# PIC32CZ8110CA80176 register map
Vendor: Microchip Technology; Series: PIC32CZCA80; File version: 0
CPU: CM7 r1p1, selectable endian, MPU, FPU, 3 interrupt priority bits
Registers are 32-bit, read-write, reset 0x0 unless marked. A register's access mark holds for its fields unless they carry their own. Offsets are from the block's base; [hi:lo] are bit positions; {n}, {i} and the like mark numbered series; <NAME> marks a mode.

## FPU — Floating Point Unit
Base 0xE000EF30; register names take the prefix FPU_
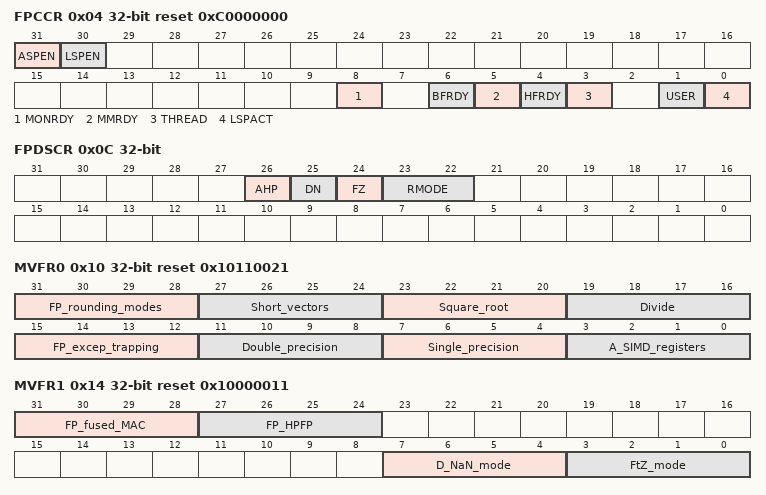
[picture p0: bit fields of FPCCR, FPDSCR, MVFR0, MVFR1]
0x04 FPCCR reset 0xC0000000 — Floating-Point Context Control Register
  [31] ASPEN, [30] LSPEN, [8] MONRDY, [6] BFRDY, [5] MMRDY, [4] HFRDY, [3] THREAD, [1] USER, [0] LSPACT
0x08 FPCAR — Floating-Point Context Address Register
  [31:3] ADDRESS — Address for FP registers in exception stack frame
0x0C FPDSCR — Floating-Point Default Status Control Register
  [26] AHP — Default value for FPSCR.AHP
  [25] DN — Default value for FPSCR.DN
  [24] FZ — Default value for FPSCR.FZ
  [23:22] RMODE — Default value for FPSCR.RMODE
    0=RN (Round to Nearest); 1=RP (Round towards Positive Infinity); 2=RM (Round towards Negative Infinity); 3=RZ (Round towards Zero)
0x10 MVFR0 ro reset 0x10110021 — Media and FP Feature Register 0
  [31:28] FP_rounding_modes, [27:24] Short_vectors, [23:20] Square_root, [19:16] Divide, [15:12] FP_excep_trapping, [11:8] Double_precision, [7:4] Single_precision, [3:0] A_SIMD_registers
0x14 MVFR1 ro reset 0x10000011 — Media and FP Feature Register 1
  [31:28] FP_fused_MAC, [27:24] FP_HPFP, [7:4] D_NaN_mode, [3:0] FtZ_mode
0x18 MVFR2 ro reset 0x40 — Media and FP Feature Register 2

## FREQM — Frequency Meter
Base 0x44060000; register names take the prefix FREQM_
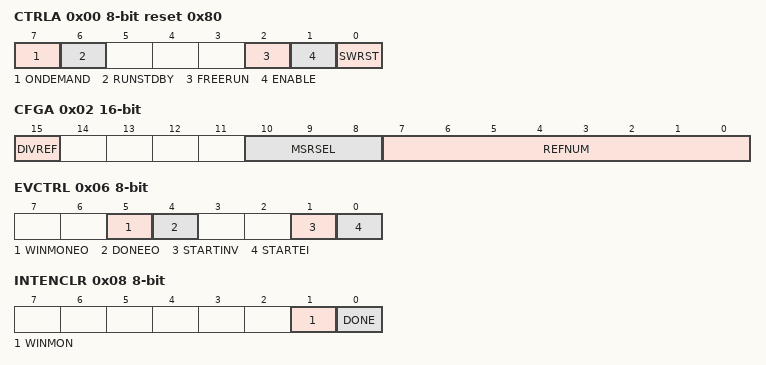
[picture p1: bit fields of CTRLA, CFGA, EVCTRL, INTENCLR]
0x00 CTRLA 8-bit reset 0x80 — Control A Register
  [7] ONDEMAND — On Demand Control
  [6] RUNSTDBY — Run In Standby
  [2] FREERUN — Free Running Mode
  [1] ENABLE
  [0] SWRST — Software Reset
0x01 CTRLB 8-bit wo — Control B Register
  [0] START — Start Measurement
0x02 CFGA 16-bit — Config A Register
  [15] DIVREF — Divide Reference Clock
    0=DIV1 (The reference clock is divided by 1); 1=DIV8 (The reference clock is divided by 8)
  [10:8] MSRSEL — Measurement Clock Selection
    0=GCLK (GCLK Input Clock); 1=CPU (CPU Input Clock)
  [7:0] REFNUM — Number of Reference Clock Cycles
0x04 CTRLC 8-bit — Control C Register
  [2:0] WINMODE — Window Monitor Mode
    0=DISABLE (No window mode (default)); 1=MODE1 (VALUE > WINLT); 2=MODE2 (VALUE < WINUT); 3=MODE3 (WINLT < VALUE < WINUT); 4=MODE4 (!(WINLT < VALUE < WINUT))
0x06 EVCTRL 8-bit — Event Control Register
  [5] WINMONEO — Window Monitor Event Out
  [4] DONEEO — Measurement Done Event Out
  [1] STARTINV — Start Measurement Event Invert Enable
  [0] STARTEI — Start Measurement Event Input Enable
0x08 INTENCLR 8-bit — Interrupt Enable Clear Register
  [1] WINMON — Window Monitor Interrupt Disable
  [0] DONE — Measurement Done Interrupt Disable
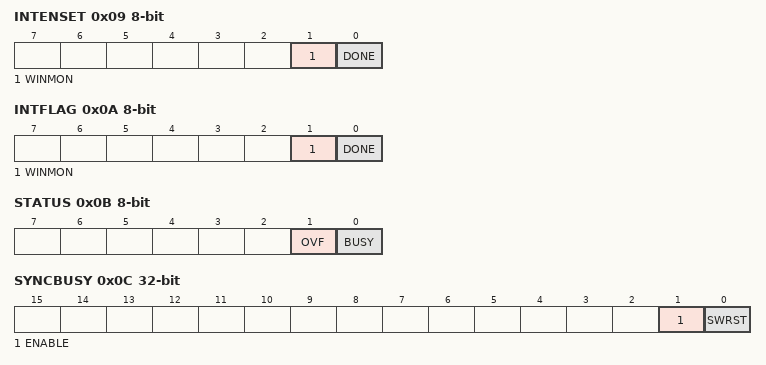
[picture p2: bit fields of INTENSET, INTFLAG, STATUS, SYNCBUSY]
0x09 INTENSET 8-bit — Interrupt Enable Set Register
  [1] WINMON — Window Monitor Interrupt Enable
  [0] DONE — Measurement Done Interrupt Enable
0x0A INTFLAG 8-bit — Interrupt Flag Register
  [1] WINMON — Window Monitor
  [0] DONE — Measurement Done
0x0B STATUS 8-bit
  [1] OVF — Sticky Count Value Overflow
  [0] BUSY — FREQM Status
0x0C SYNCBUSY ro — Synchronization Busy Register
  [1] ENABLE
  [0] SWRST — Software Reset
0x10 VALUE ro — Count Value Register
  [23:0] VALUE — Measurement Value
0x20 WINLT — Window Monitor Lower Threshold
  [23:0] WINLT — Window Lower Threshold
0x24 WINUT — Window Monitor Upper Threshold
  [23:0] WINUT — Window Upper Threshold

## GCLK — Generic Clock Generator
Base 0x44050000; register names take the prefix GCLK_
0x00 CTRLA 8-bit — Control
  [0] SWRST — Software Reset
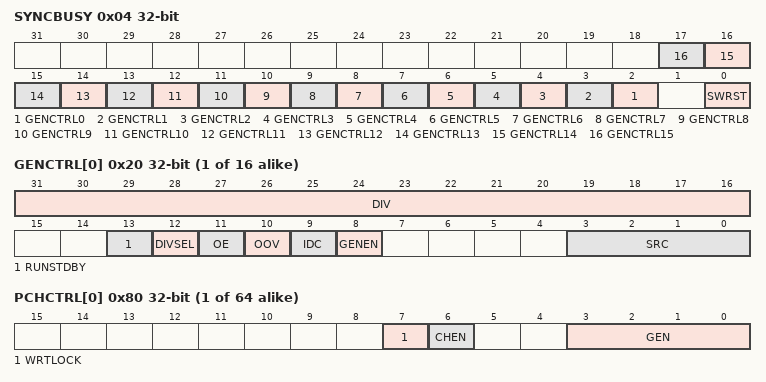
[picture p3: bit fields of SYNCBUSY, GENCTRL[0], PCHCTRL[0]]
0x04 SYNCBUSY ro — Synchronization Busy
  [n+2] GENCTRL{n} (n=0..15) — Generic Clock Generator Control {n} Synchronization Busy bit
  [0] SWRST — Software Reset Synchronization Busy bit
{0x20+4i} GENCTRL[{i}] (i=0..15) — Generic Clock Generator Control
  [31:16] DIV — Division Factor
  [13] RUNSTDBY — Run in Standby
  [12] DIVSEL — Divide Selection
    0=DIV1 (Divide input directly by divider factor); 1=DIV2 (Divide input by 2^(divider factor+ 1))
  [11] OE — Output Enable
  [10] OOV — Output Off Value
  [9] IDC — Improve Duty Cycle
  [8] GENEN — Generic Clock Generator Enable
  [3:0] SRC — Source Select
    0=XOSC (XOSC0 oscillator output); 1=GCLKIN (Generator input pad); 2=GCLKGEN1 (Generic clock generator 1 output); 3=OSCULP32K (OSCULP32K oscillator output); 4=XOSC32K (XOSC32K oscillator output); 5=DFLL (DFLL output); {v}=PLL0_{v-5} (PLL0 output {v-5}) (v=6..9); 10=PLL1_1 (Frac Divider PLL1 output 1); 11=PLL1_2 (Frac Divider PLL1 output 2); 12=PLL1_3 (PLL1 output 3); 13=PLL1_4 (PLL1 output 4)
{0x80+4i} PCHCTRL[{i}] (i=0..63) — Peripheral Clock Control
  [7] WRTLOCK — Write Lock
  [6] CHEN — Channel Enable
  [3:0] GEN — Generic Clock Generator
    {v}=GCLK{v} (Generic clock generator {v}) (v=0..15)

## Notices in the file
Copyright (c) 2017 Microchip Technology Inc.
SPDX-License-Identifier: Apache-2.0
Licensed under the Apache License, Version 2.0 (the "License");
you may not use this file except in compliance with the License.
You may obtain a copy of the License at
http://www.apache.org/licenses/LICENSE-2.0
Unless required by applicable law or agreed to in writing, software
distributed under the License is distributed on an "AS IS" BASIS,
WITHOUT WARRANTIES OR CONDITIONS OF ANY KIND, either express or implied.
See the License for the specific language governing permissions and
limitations under the License.
